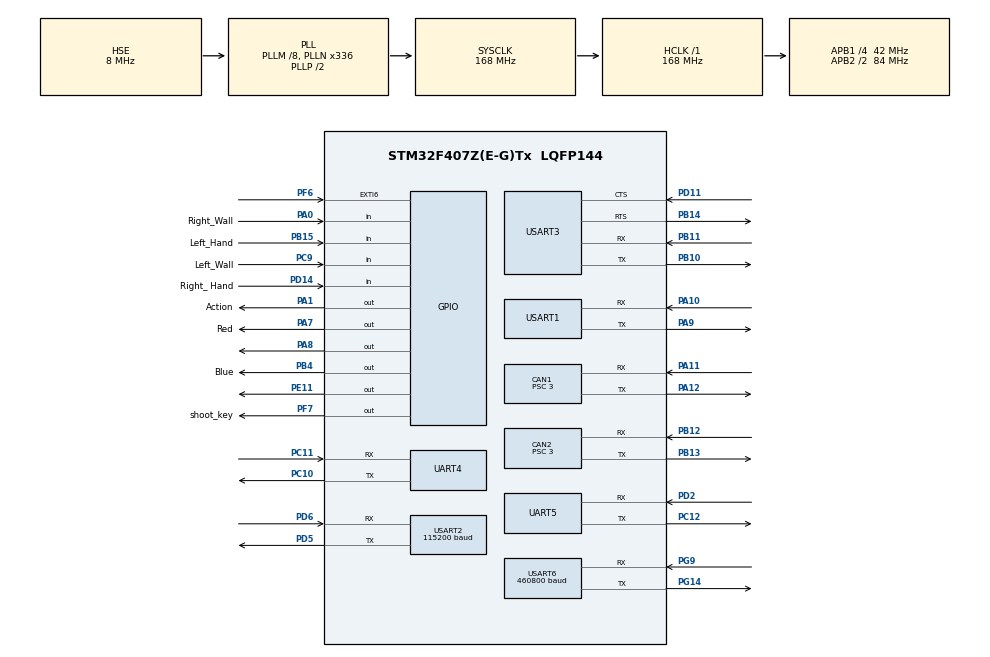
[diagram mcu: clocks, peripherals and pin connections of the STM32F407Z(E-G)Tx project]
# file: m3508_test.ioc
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CAN1.ABOM=ENABLE
CAN1.BS1=CAN_BS1_9TQ
CAN1.BS2=CAN_BS2_4TQ
CAN1.CalculateBaudRate=1000000
CAN1.CalculateTimeBit=1000
CAN1.CalculateTimeQuantum=71.42857142857143
CAN1.NART=ENABLE
CAN1.Prescaler=3
CAN2.ABOM=ENABLE
CAN2.BS1=CAN_BS1_9TQ
CAN2.BS2=CAN_BS2_4TQ
CAN2.CalculateBaudRate=1000000
CAN2.CalculateTimeBit=1000
CAN2.CalculateTimeQuantum=71.42857142857143
CAN2.NART=DISABLE
CAN2.Prescaler=3
Dma.Request0=USART6_RX
Dma.USART6_RX.0.Direction=DMA_PERIPH_TO_MEMORY
Dma.USART6_RX.0.FIFOMode=DMA_FIFOMODE_DISABLE
Dma.USART6_RX.0.Instance=DMA2_Stream1
Dma.USART6_RX.0.MemDataAlignment=DMA_MDATAALIGN_BYTE
Dma.USART6_RX.0.MemInc=DMA_MINC_ENABLE
Dma.USART6_RX.0.Mode=DMA_NORMAL
Dma.USART6_RX.0.PeriphDataAlignment=DMA_PDATAALIGN_BYTE
Dma.USART6_RX.0.PeriphInc=DMA_PINC_DISABLE
Dma.USART6_RX.0.Priority=DMA_PRIORITY_LOW
FREERTOS.Tasks01=defaultTask,24,128,StartDefaultTask,Default,NULL,Dynamic,NULL,NULL;motor_control,8,128,MotorControl,Default,NULL,Dynamic,NULL,NULL;robot_state,8,128,RobotState,Default,NULL,Dynamic,NULL,NULL;robot_move,8,128,RobotMove,Default,NULL,Dynamic,NULL,NULL
Mcu.Family=STM32F4
Mcu.Name=STM32F407Z(E-G)Tx
Mcu.Package=LQFP144
NVIC.CAN1_RX0_IRQn=true\:7\:0\:true\:false\:true\:false\:true\:true\:true
NVIC.CAN2_RX0_IRQn=true\:8\:0\:true\:false\:true\:true\:true\:true\:true
NVIC.DMA2_Stream1_IRQn=true\:5\:0\:false\:false\:true\:true\:false\:true\:true
NVIC.EXTI9_5_IRQn=true\:0\:0\:true\:false\:true\:false\:true\:true\:true
NVIC.PriorityGroup=NVIC_PRIORITYGROUP_4
NVIC.TIM3_IRQn=true\:15\:0\:false\:false\:true\:false\:false\:true\:true
NVIC.TimeBase=TIM3_IRQn
NVIC.TimeBaseIP=TIM3
NVIC.UART4_IRQn=true\:6\:0\:true\:false\:true\:false\:true\:true\:true
NVIC.UART5_IRQn=true\:5\:0\:true\:false\:true\:false\:true\:true\:true
NVIC.USART1_IRQn=true\:5\:0\:true\:false\:true\:false\:true\:true\:true
NVIC.USART2_IRQn=true\:5\:0\:true\:false\:true\:false\:true\:true\:true
NVIC.USART3_IRQn=true\:3\:0\:true\:false\:true\:false\:true\:true\:true
PA0-WKUP.GPIO_Label=Right_Wall
PA0-WKUP.GPIO_PuPd=GPIO_PULLUP
PA0-WKUP.Signal=GPIO_Input
PA1.GPIO_Label=Action
PA1.GPIO_PuPd=GPIO_PULLUP
PA1.GPIO_Speed=GPIO_SPEED_FREQ_MEDIUM
PA1.PinState=GPIO_PIN_SET
PA1.Signal=GPIO_Output
PA10.Mode=Asynchronous
PA10.Signal=USART1_RX
PA11.Mode=CAN_Activate
PA11.Signal=CAN1_RX
PA12.Mode=CAN_Activate
PA12.Signal=CAN1_TX
PA13.Mode=Serial_Wire
PA13.Signal=SYS_JTMS-SWDIO
PA14.Mode=Serial_Wire
PA14.Signal=SYS_JTCK-SWCLK
PA7.GPIO_Label=Red
PA7.GPIO_PuPd=GPIO_PULLUP
PA7.GPIO_Speed=GPIO_SPEED_FREQ_MEDIUM
PA7.PinState=GPIO_PIN_SET
PA7.Signal=GPIO_Output
PA8.GPIO_PuPd=GPIO_PULLUP
PA8.GPIO_Speed=GPIO_SPEED_FREQ_MEDIUM
PA8.PinState=GPIO_PIN_SET
PA8.Signal=GPIO_Output
PA9.Mode=Asynchronous
PA9.Signal=USART1_TX
PB10.Mode=Asynchronous
PB10.Signal=USART3_TX
PB11.Mode=Asynchronous
PB11.Signal=USART3_RX
PB12.Mode=CAN_Activate
PB12.Signal=CAN2_RX
PB13.Mode=CAN_Activate
PB13.Signal=CAN2_TX
PB14.Mode=CTS_RTS
PB14.Signal=USART3_RTS
PB15.GPIO_Label=Left_Hand
PB15.GPIO_PuPd=GPIO_PULLUP
PB15.Signal=GPIO_Input
PB4.GPIO_Label=Blue
PB4.GPIO_PuPd=GPIO_PULLUP
PB4.GPIO_Speed=GPIO_SPEED_FREQ_MEDIUM
PB4.PinState=GPIO_PIN_SET
PB4.Signal=GPIO_Output
PC10.Mode=Asynchronous
PC10.Signal=UART4_TX
PC11.Mode=Asynchronous
PC11.Signal=UART4_RX
PC12.Mode=Asynchronous
PC12.Signal=UART5_TX
PC14-OSC32_IN.Mode=LSE-External-Oscillator
PC14-OSC32_IN.Signal=RCC_OSC32_IN
PC15-OSC32_OUT.Mode=LSE-External-Oscillator
PC15-OSC32_OUT.Signal=RCC_OSC32_OUT
PC9.GPIO_Label=Left_Wall
PC9.GPIO_PuPd=GPIO_PULLUP
PC9.Signal=GPIO_Input
PD11.Mode=CTS_RTS
PD11.Signal=USART3_CTS
PD14.GPIO_Label=Right_ Hand
PD14.GPIO_PuPd=GPIO_PULLUP
PD14.Signal=GPIO_Input
PD2.Mode=Asynchronous
PD2.Signal=UART5_RX
PD5.Mode=Asynchronous
PD5.Signal=USART2_TX
PD6.Mode=Asynchronous
PD6.Signal=USART2_RX
PE11.GPIO_PuPd=GPIO_PULLUP
PE11.GPIO_Speed=GPIO_SPEED_FREQ_MEDIUM
PE11.PinState=GPIO_PIN_SET
PE11.Signal=GPIO_Output
PF6.Signal=GPXTI6
PF7.GPIO_Label=shoot_key
PF7.GPIO_ModeDefaultOutputPP=GPIO_MODE_OUTPUT_PP
PF7.GPIO_PuPd=GPIO_PULLDOWN
PF7.GPIO_Speed=GPIO_SPEED_FREQ_HIGH
PF7.PinState=GPIO_PIN_RESET
PF7.Signal=GPIO_Output
PG14.Mode=Asynchronous
PG14.Signal=USART6_TX
PG9.Mode=Asynchronous
PG9.Signal=USART6_RX
PH0-OSC_IN.Mode=HSE-External-Oscillator
PH0-OSC_IN.Signal=RCC_OSC_IN
PH1-OSC_OUT.Mode=HSE-External-Oscillator
PH1-OSC_OUT.Signal=RCC_OSC_OUT
ProjectManager.HeapSize=0x200
ProjectManager.StackSize=0x400
ProjectManager.TargetToolchain=MDK-ARM V5.32
<<<<<<< HEAD
=======
>>>>>>> 944f7e49b9ca7249e370900b25af451d08e604c0
RCC.48MHZClocksFreq_Value=84000000
RCC.AHBFreq_Value=168000000
RCC.APB1CLKDivider=RCC_HCLK_DIV4
RCC.APB1Freq_Value=42000000
RCC.APB1TimFreq_Value=84000000
RCC.APB2CLKDivider=RCC_HCLK_DIV2
RCC.APB2Freq_Value=84000000
RCC.APB2TimFreq_Value=168000000
RCC.CortexFreq_Value=168000000
RCC.HCLKFreq_Value=168000000
RCC.HSE_VALUE=8000000
RCC.HSI_VALUE=16000000
RCC.PLLM=8
RCC.PLLN=336
RCC.PLLSourceVirtual=RCC_PLLSOURCE_HSE
RCC.SYSCLKFreq_VALUE=168000000
RCC.SYSCLKSource=RCC_SYSCLKSOURCE_PLLCLK
RCC.VCOOutputFreq_Value=336000000
UART4.VirtualMode=Asynchronous
UART5.VirtualMode=Asynchronous
USART1.VirtualMode=VM_ASYNC
USART2.BaudRate=115200
USART2.VirtualMode=VM_ASYNC
USART3.VirtualMode=VM_ASYNC
<<<<<<< HEAD
USART6.BaudRate=9600
=======
USART6.BaudRate=460800
>>>>>>> 944f7e49b9ca7249e370900b25af451d08e604c0
USART6.VirtualMode=VM_ASYNC
VP_FREERTOS_VS_CMSIS_V2.Mode=CMSIS_V2
VP_SYS_VS_tim3.Mode=TIM3
board=custom

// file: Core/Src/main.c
/* USER CODE BEGIN Header */
/**
  ******************************************************************************
  * @file           : main.c
  * @brief          : Main program body
  ******************************************************************************
  * @attention
  *
  * Copyright (c) 2024 STMicroelectronics.
  * All rights reserved.
  *
  * This software is licensed under terms that can be found in the LICENSE file
  * in the root directory of this software component.
  * If no LICENSE file comes with this software, it is provided AS-IS.
  *
  ******************************************************************************
  */
/* USER CODE END Header */
#include "main.h"
#include "cmsis_os.h"
#include "can.h"
#include "dma.h"
#include "usart.h"
#include "gpio.h"

/* USER CODE BEGIN Includes */
#include "Task_Process.h"
/* USER CODE END Includes */

void SystemClock_Config(void);
void MX_FREERTOS_Init(void);

int main(void)
{

  /* MCU Configuration--------------------------------------------------------*/

  /* Reset of all peripherals, Initializes the Flash interface and the Systick. */
  HAL_Init();

  /* Configure the system clock */
  SystemClock_Config();

  /* Initialize all configured peripherals */
  MX_GPIO_Init();
<<<<<<< HEAD
=======
  MX_DMA_Init();
>>>>>>> 944f7e49b9ca7249e370900b25af451d08e604c0
  MX_CAN1_Init();
  MX_USART1_UART_Init();
  MX_CAN2_Init();
  MX_USART3_UART_Init();
  MX_UART4_Init();
  MX_USART2_UART_Init();
  MX_USART6_UART_Init();
  MX_UART5_Init();
  /* USER CODE BEGIN 2 */
  USART_IT_Init();
  /* USER CODE END 2 */

  /* Init scheduler */
  osKernelInitialize();

  /* Call init function for freertos objects (in freertos.c) */
<<<<<<< HEAD
  //MX_FREERTOS_Init();
=======
 // MX_FREERTOS_Init();
>>>>>>> 944f7e49b9ca7249e370900b25af451d08e604c0

  /* Start scheduler */
  //osKernelStart();

  /* We should never get here as control is now taken by the scheduler */
  /* Infinite loop */
  /* USER CODE BEGIN WHILE */
  My_Task_Creator();
  osKernelStart();

  while (1)
  {
    /* USER CODE END WHILE */

  }
}

void SystemClock_Config(void)
{
  RCC_OscInitTypeDef RCC_OscInitStruct = {0};
  RCC_ClkInitTypeDef RCC_ClkInitStruct = {0};

  /** Configure the main internal regulator output voltage
  */
  __HAL_RCC_PWR_CLK_ENABLE();
  __HAL_PWR_VOLTAGESCALING_CONFIG(PWR_REGULATOR_VOLTAGE_SCALE1);

  /** Initializes the RCC Oscillators according to the specified parameters
  * in the RCC_OscInitTypeDef structure.
  */
  RCC_OscInitStruct.OscillatorType = RCC_OSCILLATORTYPE_HSE;
  RCC_OscInitStruct.HSEState = RCC_HSE_ON;
  RCC_OscInitStruct.PLL.PLLState = RCC_PLL_ON;
  RCC_OscInitStruct.PLL.PLLSource = RCC_PLLSOURCE_HSE;
  RCC_OscInitStruct.PLL.PLLM = 8;
  RCC_OscInitStruct.PLL.PLLN = 336;
  RCC_OscInitStruct.PLL.PLLP = RCC_PLLP_DIV2;
  RCC_OscInitStruct.PLL.PLLQ = 4;
  if (HAL_RCC_OscConfig(&RCC_OscInitStruct) != HAL_OK)
  {
    Error_Handler();
  }

  /** Initializes the CPU, AHB and APB buses clocks
  */
  RCC_ClkInitStruct.ClockType = RCC_CLOCKTYPE_HCLK|RCC_CLOCKTYPE_SYSCLK
                              |RCC_CLOCKTYPE_PCLK1|RCC_CLOCKTYPE_PCLK2;
  RCC_ClkInitStruct.SYSCLKSource = RCC_SYSCLKSOURCE_PLLCLK;
  RCC_ClkInitStruct.AHBCLKDivider = RCC_SYSCLK_DIV1;
  RCC_ClkInitStruct.APB1CLKDivider = RCC_HCLK_DIV4;
  RCC_ClkInitStruct.APB2CLKDivider = RCC_HCLK_DIV2;

  if (HAL_RCC_ClockConfig(&RCC_ClkInitStruct, FLASH_LATENCY_5) != HAL_OK)
  {
    Error_Handler();
  }
}

void HAL_TIM_PeriodElapsedCallback(TIM_HandleTypeDef *htim)
{
  if (htim->Instance == TIM3) {
    HAL_IncTick();
  }
}

void Error_Handler(void)
{
  __disable_irq();
  while (1)
  {
  }
}

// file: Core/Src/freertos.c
/* USER CODE BEGIN Header */
/**
  ******************************************************************************
  * File Name          : freertos.c
  * Description        : Code for freertos applications
  ******************************************************************************
  * @attention
  *
  * Copyright (c) 2024 STMicroelectronics.
  * All rights reserved.
  *
  * This software is licensed under terms that can be found in the LICENSE file
  * in the root directory of this software component.
  * If no LICENSE file comes with this software, it is provided AS-IS.
  *
  ******************************************************************************
  */
/* USER CODE END Header */

#include "FreeRTOS.h"
#include "task.h"
#include "main.h"
#include "cmsis_os.h"

/* Definitions for defaultTask */
osThreadId_t defaultTaskHandle;
const osThreadAttr_t defaultTask_attributes = {
  .name = "defaultTask",
  .stack_size = 128 * 4,
  .priority = (osPriority_t) osPriorityNormal,
};
/* Definitions for motor_control */
osThreadId_t motor_controlHandle;
const osThreadAttr_t motor_control_attributes = {
  .name = "motor_control",
  .stack_size = 128 * 4,
  .priority = (osPriority_t) osPriorityLow,
};
/* Definitions for robot_state */
osThreadId_t robot_stateHandle;
const osThreadAttr_t robot_state_attributes = {
  .name = "robot_state",
  .stack_size = 128 * 4,
  .priority = (osPriority_t) osPriorityLow,
};
/* Definitions for robot_move */
osThreadId_t robot_moveHandle;
const osThreadAttr_t robot_move_attributes = {
  .name = "robot_move",
  .stack_size = 128 * 4,
  .priority = (osPriority_t) osPriorityLow,
};

void StartDefaultTask(void *argument);
void MotorControl(void *argument);
void RobotState(void *argument);
void RobotMove(void *argument);

void MX_FREERTOS_Init(void); /* (MISRA C 2004 rule 8.1) */

void MX_FREERTOS_Init(void) {

  /* Create the thread(s) */
  /* creation of defaultTask */
  defaultTaskHandle = osThreadNew(StartDefaultTask, NULL, &defaultTask_attributes);

  /* creation of motor_control */
  motor_controlHandle = osThreadNew(MotorControl, NULL, &motor_control_attributes);

  /* creation of robot_state */
  robot_stateHandle = osThreadNew(RobotState, NULL, &robot_state_attributes);

  /* creation of robot_move */
  robot_moveHandle = osThreadNew(RobotMove, NULL, &robot_move_attributes);

}

void StartDefaultTask(void *argument)
{
  for(;;)
  {
    osDelay(1);
  }
}

void MotorControl(void *argument)
{
  for(;;)
  {
    osDelay(1);
  }
}

void RobotState(void *argument)
{
  for(;;)
  {
    osDelay(1);
  }
}

void RobotMove(void *argument)
{
  for(;;)
  {
    osDelay(1);
  }
}
